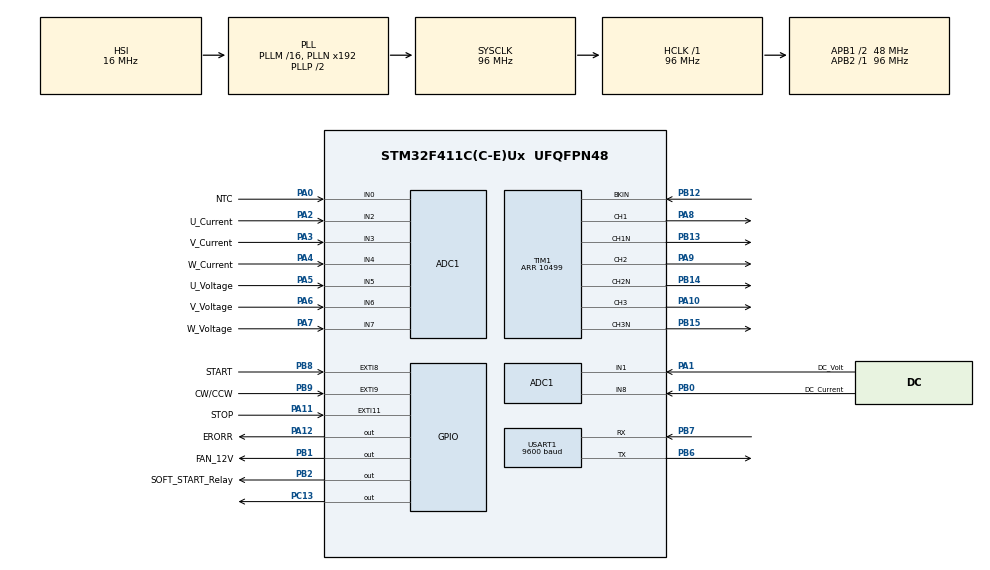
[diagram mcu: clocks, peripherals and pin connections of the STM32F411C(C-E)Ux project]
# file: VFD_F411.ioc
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ADC1.Channel-0\#ChannelRegularConversion=ADC_CHANNEL_0
ADC1.Channel-1\#ChannelRegularConversion=ADC_CHANNEL_1
ADC1.Channel-10\#ChannelRegularConversion=ADC_CHANNEL_8
ADC1.Channel-2\#ChannelRegularConversion=ADC_CHANNEL_2
ADC1.Channel-3\#ChannelRegularConversion=ADC_CHANNEL_3
ADC1.Channel-4\#ChannelRegularConversion=ADC_CHANNEL_4
ADC1.Channel-7\#ChannelRegularConversion=ADC_CHANNEL_5
ADC1.Channel-8\#ChannelRegularConversion=ADC_CHANNEL_6
ADC1.Channel-9\#ChannelRegularConversion=ADC_CHANNEL_7
ADC1.ContinuousConvMode=ENABLE
ADC1.DMAContinuousRequests=ENABLE
ADC1.EOCSelection=ADC_EOC_SEQ_CONV
ADC1.EnableAnalogWatchDog=true
ADC1.HighThreshold=2730
ADC1.ITMode=ENABLE
ADC1.InjNumberOfConversion=0
ADC1.NbrOfConversion=9
ADC1.NbrOfConversionFlag=1
ADC1.Rank-0\#ChannelRegularConversion=1
ADC1.Rank-1\#ChannelRegularConversion=2
ADC1.Rank-10\#ChannelRegularConversion=9
ADC1.Rank-2\#ChannelRegularConversion=3
ADC1.Rank-3\#ChannelRegularConversion=4
ADC1.Rank-4\#ChannelRegularConversion=5
ADC1.Rank-7\#ChannelRegularConversion=6
ADC1.Rank-8\#ChannelRegularConversion=7
ADC1.Rank-9\#ChannelRegularConversion=8
ADC1.SamplingTime-0\#ChannelRegularConversion=ADC_SAMPLETIME_84CYCLES
ADC1.SamplingTime-1\#ChannelRegularConversion=ADC_SAMPLETIME_84CYCLES
ADC1.SamplingTime-10\#ChannelRegularConversion=ADC_SAMPLETIME_84CYCLES
ADC1.SamplingTime-2\#ChannelRegularConversion=ADC_SAMPLETIME_84CYCLES
ADC1.SamplingTime-3\#ChannelRegularConversion=ADC_SAMPLETIME_84CYCLES
ADC1.SamplingTime-4\#ChannelRegularConversion=ADC_SAMPLETIME_84CYCLES
ADC1.SamplingTime-7\#ChannelRegularConversion=ADC_SAMPLETIME_84CYCLES
ADC1.SamplingTime-8\#ChannelRegularConversion=ADC_SAMPLETIME_84CYCLES
ADC1.SamplingTime-9\#ChannelRegularConversion=ADC_SAMPLETIME_84CYCLES
ADC1.WatchdogChannel=ADC_CHANNEL_0
ADC1.master=1
Dma.ADC1.4.Direction=DMA_PERIPH_TO_MEMORY
Dma.ADC1.4.FIFOMode=DMA_FIFOMODE_DISABLE
Dma.ADC1.4.Instance=DMA2_Stream0
Dma.ADC1.4.MemDataAlignment=DMA_MDATAALIGN_HALFWORD
Dma.ADC1.4.MemInc=DMA_MINC_ENABLE
Dma.ADC1.4.Mode=DMA_CIRCULAR
Dma.ADC1.4.PeriphDataAlignment=DMA_PDATAALIGN_HALFWORD
Dma.ADC1.4.PeriphInc=DMA_PINC_DISABLE
Dma.ADC1.4.Priority=DMA_PRIORITY_HIGH
Dma.Request0=TIM1_CH1
Dma.Request1=TIM1_CH2
Dma.Request2=TIM1_CH3
Dma.Request3=USART1_RX
Dma.Request4=ADC1
Dma.Request5=USART1_TX
Dma.TIM1_CH1.0.Direction=DMA_MEMORY_TO_PERIPH
Dma.TIM1_CH1.0.FIFOMode=DMA_FIFOMODE_DISABLE
Dma.TIM1_CH1.0.Instance=DMA2_Stream1
Dma.TIM1_CH1.0.MemDataAlignment=DMA_MDATAALIGN_HALFWORD
Dma.TIM1_CH1.0.MemInc=DMA_MINC_ENABLE
Dma.TIM1_CH1.0.Mode=DMA_CIRCULAR
Dma.TIM1_CH1.0.PeriphDataAlignment=DMA_PDATAALIGN_HALFWORD
Dma.TIM1_CH1.0.PeriphInc=DMA_PINC_DISABLE
Dma.TIM1_CH1.0.Priority=DMA_PRIORITY_HIGH
Dma.TIM1_CH2.1.Direction=DMA_MEMORY_TO_PERIPH
Dma.TIM1_CH2.1.FIFOMode=DMA_FIFOMODE_DISABLE
Dma.TIM1_CH2.1.Instance=DMA2_Stream2
Dma.TIM1_CH2.1.MemDataAlignment=DMA_MDATAALIGN_HALFWORD
Dma.TIM1_CH2.1.MemInc=DMA_MINC_ENABLE
Dma.TIM1_CH2.1.Mode=DMA_CIRCULAR
Dma.TIM1_CH2.1.PeriphDataAlignment=DMA_PDATAALIGN_HALFWORD
Dma.TIM1_CH2.1.PeriphInc=DMA_PINC_DISABLE
Dma.TIM1_CH2.1.Priority=DMA_PRIORITY_HIGH
Dma.TIM1_CH3.2.Direction=DMA_MEMORY_TO_PERIPH
Dma.TIM1_CH3.2.FIFOMode=DMA_FIFOMODE_DISABLE
Dma.TIM1_CH3.2.Instance=DMA2_Stream6
Dma.TIM1_CH3.2.MemDataAlignment=DMA_MDATAALIGN_HALFWORD
Dma.TIM1_CH3.2.MemInc=DMA_MINC_ENABLE
Dma.TIM1_CH3.2.Mode=DMA_CIRCULAR
Dma.TIM1_CH3.2.PeriphDataAlignment=DMA_PDATAALIGN_HALFWORD
Dma.TIM1_CH3.2.PeriphInc=DMA_PINC_DISABLE
Dma.TIM1_CH3.2.Priority=DMA_PRIORITY_HIGH
Dma.USART1_RX.3.Direction=DMA_PERIPH_TO_MEMORY
Dma.USART1_RX.3.FIFOMode=DMA_FIFOMODE_DISABLE
Dma.USART1_RX.3.Instance=DMA2_Stream5
Dma.USART1_RX.3.MemDataAlignment=DMA_MDATAALIGN_BYTE
Dma.USART1_RX.3.MemInc=DMA_MINC_ENABLE
Dma.USART1_RX.3.Mode=DMA_CIRCULAR
Dma.USART1_RX.3.PeriphDataAlignment=DMA_PDATAALIGN_BYTE
Dma.USART1_RX.3.PeriphInc=DMA_PINC_DISABLE
Dma.USART1_RX.3.Priority=DMA_PRIORITY_HIGH
Dma.USART1_TX.5.Direction=DMA_MEMORY_TO_PERIPH
Dma.USART1_TX.5.FIFOMode=DMA_FIFOMODE_DISABLE
Dma.USART1_TX.5.Instance=DMA2_Stream7
Dma.USART1_TX.5.MemDataAlignment=DMA_MDATAALIGN_BYTE
Dma.USART1_TX.5.MemInc=DMA_MINC_ENABLE
Dma.USART1_TX.5.Mode=DMA_NORMAL
Dma.USART1_TX.5.PeriphDataAlignment=DMA_PDATAALIGN_BYTE
Dma.USART1_TX.5.PeriphInc=DMA_PINC_DISABLE
Dma.USART1_TX.5.Priority=DMA_PRIORITY_MEDIUM
Mcu.Family=STM32F4
Mcu.Name=STM32F411C(C-E)Ux
Mcu.Package=UFQFPN48
NVIC.ADC_IRQn=true\:1\:0\:true\:false\:true\:true\:true\:true
NVIC.DMA2_Stream0_IRQn=true\:1\:0\:true\:false\:true\:false\:true\:true
NVIC.DMA2_Stream1_IRQn=true\:0\:0\:false\:false\:true\:false\:true\:true
NVIC.DMA2_Stream2_IRQn=true\:0\:0\:false\:false\:true\:false\:true\:true
NVIC.DMA2_Stream5_IRQn=true\:1\:0\:true\:false\:true\:false\:true\:true
NVIC.DMA2_Stream6_IRQn=true\:0\:0\:false\:false\:true\:false\:true\:true
NVIC.DMA2_Stream7_IRQn=true\:0\:0\:false\:false\:true\:false\:true\:true
NVIC.EXTI15_10_IRQn=true\:0\:0\:false\:false\:true\:true\:true\:true
NVIC.EXTI9_5_IRQn=true\:0\:0\:false\:false\:true\:true\:true\:true
NVIC.PriorityGroup=NVIC_PRIORITYGROUP_4
NVIC.TIM1_BRK_TIM9_IRQn=true\:1\:0\:true\:false\:true\:true\:true\:true
NVIC.TIM1_UP_TIM10_IRQn=true\:1\:0\:true\:false\:true\:true\:true\:true
NVIC.USART1_IRQn=true\:2\:0\:true\:false\:true\:true\:true\:true
PA0-WKUP.GPIO_Label=NTC
PA0-WKUP.Signal=ADCx_IN0
PA1.GPIO_Label=DC_Volt
PA1.Signal=ADCx_IN1
PA10.GPIO_Speed=GPIO_SPEED_FREQ_MEDIUM
PA10.Signal=S_TIM1_CH3
PA11.GPIO_Label=STOP
PA11.GPIO_ModeDefaultEXTI=GPIO_MODE_IT_FALLING
PA11.GPIO_PuPd=GPIO_PULLUP
PA11.Signal=GPXTI11
PA12.GPIO_Label=ERORR 
PA12.GPIO_Speed=GPIO_SPEED_FREQ_MEDIUM
PA12.Signal=GPIO_Output
PA13.Mode=Serial_Wire
PA13.Signal=SYS_JTMS-SWDIO
PA14.Mode=Serial_Wire
PA14.Signal=SYS_JTCK-SWCLK
PA2.GPIO_Label=U_Current
PA2.Signal=ADCx_IN2
PA3.GPIO_Label=V_Current
PA3.Signal=ADCx_IN3
PA4.GPIO_Label=W_Current
PA4.Signal=ADCx_IN4
PA5.GPIO_Label=U_Voltage
PA5.Signal=ADCx_IN5
PA6.GPIO_Label=V_Voltage
PA6.Signal=ADCx_IN6
PA7.GPIO_Label=W_Voltage
PA7.Signal=ADCx_IN7
PA8.GPIO_Speed=GPIO_SPEED_FREQ_MEDIUM
PA8.Signal=S_TIM1_CH1
PA9.GPIO_Speed=GPIO_SPEED_FREQ_MEDIUM
PA9.Signal=S_TIM1_CH2
PB0.GPIO_Label=DC_Current
PB0.Signal=ADCx_IN8
PB1.GPIO_Label=FAN_12V
PB1.Signal=GPIO_Output
PB12.GPIO_PuPd=GPIO_PULLUP
PB12.Mode=Activate-Break-Input
PB12.Signal=TIM1_BKIN
PB13.GPIO_Speed=GPIO_SPEED_FREQ_MEDIUM
PB13.Mode=PWM Generation1 CH1 CH1N
PB13.Signal=TIM1_CH1N
PB14.GPIO_Speed=GPIO_SPEED_FREQ_MEDIUM
PB14.Mode=PWM Generation2 CH2 CH2N
PB14.Signal=TIM1_CH2N
PB15.GPIO_Speed=GPIO_SPEED_FREQ_MEDIUM
PB15.Mode=PWM Generation3 CH3 CH3N
PB15.Signal=TIM1_CH3N
PB2.GPIO_Label=SOFT_START_Relay
PB2.Signal=GPIO_Output
PB6.GPIO_Speed=GPIO_SPEED_FREQ_MEDIUM
PB6.Mode=Asynchronous
PB6.Signal=USART1_TX
PB7.GPIO_ModeDefaultPP=GPIO_MODE_AF_PP
PB7.GPIO_PuPd=GPIO_PULLUP
PB7.GPIO_Speed=GPIO_SPEED_FREQ_HIGH
PB7.Mode=Asynchronous
PB7.Signal=USART1_RX
PB8.GPIO_Label=START
PB8.GPIO_ModeDefaultEXTI=GPIO_MODE_IT_FALLING
PB8.GPIO_PuPd=GPIO_PULLUP
PB8.Signal=GPXTI8
PB9.GPIO_Label=CW/CCW
PB9.GPIO_ModeDefaultEXTI=GPIO_MODE_IT_FALLING
PB9.GPIO_PuPd=GPIO_PULLUP
PB9.Signal=GPXTI9
PC13-ANTI_TAMP.Signal=GPIO_Output
PH0\ -\ OSC_IN.Mode=HSE-External-Oscillator
PH0\ -\ OSC_IN.Signal=RCC_OSC_IN
PH1\ -\ OSC_OUT.Mode=HSE-External-Oscillator
PH1\ -\ OSC_OUT.Signal=RCC_OSC_OUT
ProjectManager.HeapSize=0x200
ProjectManager.StackSize=0x400
ProjectManager.TargetToolchain=MDK-ARM V5.32
RCC.48MHZClocksFreq_Value=48000000
RCC.AHBFreq_Value=96000000
RCC.APB1CLKDivider=RCC_HCLK_DIV2
RCC.APB1Freq_Value=48000000
RCC.APB1TimFreq_Value=96000000
RCC.APB2Freq_Value=96000000
RCC.APB2TimFreq_Value=96000000
RCC.CortexFreq_Value=96000000
RCC.HCLKFreq_Value=96000000
RCC.HSE_VALUE=25000000
RCC.HSI_VALUE=16000000
RCC.LSE_VALUE=32768
RCC.PLLM=8
RCC.PLLN=96
RCC.SYSCLKFreq_VALUE=96000000
RCC.SYSCLKSource=RCC_SYSCLKSOURCE_PLLCLK
RCC.VCOOutputFreq_Value=192000000
SH.ADCx_IN0.0=ADC1_IN0,IN0
SH.ADCx_IN1.0=ADC1_IN1,IN1
SH.ADCx_IN2.0=ADC1_IN2,IN2
SH.ADCx_IN3.0=ADC1_IN3,IN3
SH.ADCx_IN4.0=ADC1_IN4,IN4
SH.ADCx_IN5.0=ADC1_IN5,IN5
SH.ADCx_IN6.0=ADC1_IN6,IN6
SH.ADCx_IN7.0=ADC1_IN7,IN7
SH.ADCx_IN8.0=ADC1_IN8,IN8
SH.S_TIM1_CH1.0=TIM1_CH1,PWM Generation1 CH1 CH1N
SH.S_TIM1_CH2.0=TIM1_CH2,PWM Generation2 CH2 CH2N
SH.S_TIM1_CH3.0=TIM1_CH3,PWM Generation3 CH3 CH3N
TIM1.AutoReloadPreload=TIM_AUTORELOAD_PRELOAD_ENABLE
TIM1.AutomaticOutput=TIM_AUTOMATICOUTPUT_DISABLE
TIM1.BreakPolarity=TIM_BREAKPOLARITY_LOW
TIM1.BreakState=TIM_BREAK_ENABLE
TIM1.Channel-PWM\ Generation1\ CH1\ CH1N=TIM_CHANNEL_1
TIM1.Channel-PWM\ Generation2\ CH2\ CH2N=TIM_CHANNEL_2
TIM1.Channel-PWM\ Generation3\ CH3\ CH3N=TIM_CHANNEL_3
TIM1.CounterMode=TIM_COUNTERMODE_UP
TIM1.DeadTime=139
TIM1.LockLevel=TIM_LOCKLEVEL_1
TIM1.OCFastMode_PWM-PWM\ Generation1\ CH1\ CH1N=TIM_OCFAST_DISABLE
TIM1.OCFastMode_PWM-PWM\ Generation2\ CH2\ CH2N=TIM_OCFAST_DISABLE
TIM1.OCFastMode_PWM-PWM\ Generation3\ CH3\ CH3N=TIM_OCFAST_DISABLE
TIM1.OCNIdleState_1=TIM_OCNIDLESTATE_RESET
TIM1.OCNIdleState_2=TIM_OCNIDLESTATE_RESET
TIM1.OCNIdleState_3=TIM_OCNIDLESTATE_RESET
TIM1.OCNPolarity_1=TIM_OCNPOLARITY_HIGH
TIM1.OCNPolarity_2=TIM_OCNPOLARITY_HIGH
TIM1.OCNPolarity_3=TIM_OCNPOLARITY_HIGH
TIM1.OCPolarity_1=TIM_OCPOLARITY_HIGH
TIM1.OCPolarity_2=TIM_OCPOLARITY_HIGH
TIM1.OCPolarity_3=TIM_OCPOLARITY_HIGH
TIM1.OffStateIDLEMode=TIM_OSSI_ENABLE
TIM1.OffStateRunMode=TIM_OSSR_ENABLE
TIM1.Period=10499
TIM1.TIM_MasterOutputTrigger=TIM_TRGO_UPDATE
TIM1.TIM_MasterSlaveMode=TIM_MASTERSLAVEMODE_ENABLE
TIM10.AutoReloadPreload=TIM_AUTORELOAD_PRELOAD_ENABLE
TIM10.Period=999
TIM10.Prescaler=95
USART1.BaudRate=9600
USART1.VirtualMode=VM_ASYNC
VP_TIM10_VS_ClockSourceINT.Mode=Enable_Timer
board=custom

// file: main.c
/* USER CODE BEGIN Header */
/**
  ******************************************************************************
  * @file           : main.c
  * @brief          : Application entry point — FVD_20N60 3-phase IGBT drive.
  *
  *  Boots the F411, configures the clock tree for a 96 MHz SYSCLK (this is the
  *  value implied by the generated timers: TIM10 with PSC=95/ARR=999 yields a
  *  1 kHz tick only when its APB2 timer clock is 96 MHz, and TIM1 ARR=10499
  *  then gives the ~9.14 kHz PWM), runs every MX_*_Init() exactly as generated,
  *  and hands control to the application layer (App_Init / App_Task in app.c).
  *
  *  IMPORTANT: the HAL interrupt callbacks (TIM period-elapsed, TIM break, ADC
  *  conv-complete, ADC watchdog, EXTI, UART RX) are implemented in app.c. Do not
  *  re-declare them here.
  *
  *  NOTE ON THE CLOCK: this board has no external crystal in the schematic, so
  *  the config below runs the PLL from the internal HSI (16 MHz). If your .ioc
  *  actually uses an HSE crystal, keep the SystemClock_Config that CubeMX
  *  generated for your project instead of this one — everything else is unchanged.
  ******************************************************************************
  * @attention
  *
  * Copyright (c) 2026 STMicroelectronics.
  * All rights reserved.
  *
  * This software is licensed under terms that can be found in the LICENSE file
  * in the root directory of this software component.
  * If no LICENSE file comes with this software, it is provided AS-IS.
  *
  ******************************************************************************
  */
/* USER CODE END Header */
#include "main.h"
#include "adc.h"
#include "dma.h"
#include "tim.h"
#include "usart.h"
#include "gpio.h"

/* USER CODE BEGIN Includes */
#include "app.h"
/* USER CODE END Includes */

void SystemClock_Config(void);

int main(void)
{

  /* MCU Configuration--------------------------------------------------------*/

  /* Reset of all peripherals, Initializes the Flash interface and the Systick. */
  HAL_Init();

  /* Configure the system clock */
  SystemClock_Config();

  /* Initialize all configured peripherals */
  MX_GPIO_Init();
  MX_DMA_Init();          /* must precede peripherals that link DMA          */
  MX_ADC1_Init();
  MX_TIM1_Init();
  MX_TIM10_Init();
  MX_USART1_UART_Init();

  /* USER CODE BEGIN 2 */
	HAL_GPIO_WritePin(ERORR_GPIO_Port, ERORR_Pin, GPIO_PIN_SET);
  App_Init();             /* start ADC/PWM/TIM10/UART, arm control ISR, BT    */
  /* USER CODE END 2 */

  /* Infinite loop */
  /* USER CODE BEGIN WHILE */
  while (1)
  {
    App_Task();           /* non-blocking: BT commands, telemetry, LED/fan    */
    /* USER CODE END WHILE */

  }
}

void SystemClock_Config(void)
{
  RCC_OscInitTypeDef RCC_OscInitStruct = {0};
  RCC_ClkInitTypeDef RCC_ClkInitStruct = {0};

  /* Voltage scaling for the targeted clock frequency */
  __HAL_RCC_PWR_CLK_ENABLE();
  __HAL_PWR_VOLTAGESCALING_CONFIG(PWR_REGULATOR_VOLTAGE_SCALE1);

  /* HSI (16 MHz) -> PLL : /16 -> x192 -> /2 = 96 MHz ; PLLQ /4 = 48 MHz */
  RCC_OscInitStruct.OscillatorType      = RCC_OSCILLATORTYPE_HSI;
  RCC_OscInitStruct.HSIState            = RCC_HSI_ON;
  RCC_OscInitStruct.HSICalibrationValue = RCC_HSICALIBRATION_DEFAULT;
  RCC_OscInitStruct.PLL.PLLState        = RCC_PLL_ON;
  RCC_OscInitStruct.PLL.PLLSource       = RCC_PLLSOURCE_HSI;
  RCC_OscInitStruct.PLL.PLLM            = 16;
  RCC_OscInitStruct.PLL.PLLN            = 192;
  RCC_OscInitStruct.PLL.PLLP            = RCC_PLLP_DIV2;
  RCC_OscInitStruct.PLL.PLLQ            = 4;
  if (HAL_RCC_OscConfig(&RCC_OscInitStruct) != HAL_OK)
  {
    Error_Handler();
  }

  /* SYSCLK=96 MHz, HCLK=96 MHz, APB1=48 MHz (/2), APB2=96 MHz (/1) */
  RCC_ClkInitStruct.ClockType      = RCC_CLOCKTYPE_HCLK   | RCC_CLOCKTYPE_SYSCLK
                                   | RCC_CLOCKTYPE_PCLK1  | RCC_CLOCKTYPE_PCLK2;
  RCC_ClkInitStruct.SYSCLKSource   = RCC_SYSCLKSOURCE_PLLCLK;
  RCC_ClkInitStruct.AHBCLKDivider  = RCC_SYSCLK_DIV1;
  RCC_ClkInitStruct.APB1CLKDivider = RCC_HCLK_DIV2;
  RCC_ClkInitStruct.APB2CLKDivider = RCC_HCLK_DIV1;
  if (HAL_RCC_ClockConfig(&RCC_ClkInitStruct, FLASH_LATENCY_3) != HAL_OK)
  {
    Error_Handler();
  }
}

void Error_Handler(void)
{
  /* USER CODE BEGIN Error_Handler_Debug */
 __disable_irq();
    HAL_Delay(100);
    HAL_NVIC_SystemReset(); // إعادة تشغيل النظام
    while(1)
  {
    /* a hard error: leave the inverter outputs disabled and trap here */
  }
  /* USER CODE END Error_Handler_Debug */
}

#ifdef USE_FULL_ASSERT
/**
  * @brief  Reports the name of the source file and the source line number
  *         where the assert_param error has occurred.
  */
void assert_failed(uint8_t *file, uint32_t line)
{
  /* USER CODE BEGIN 6 */
  (void)file; (void)line;
  /* USER CODE END 6 */
}
#endif /* USE_FULL_ASSERT */
